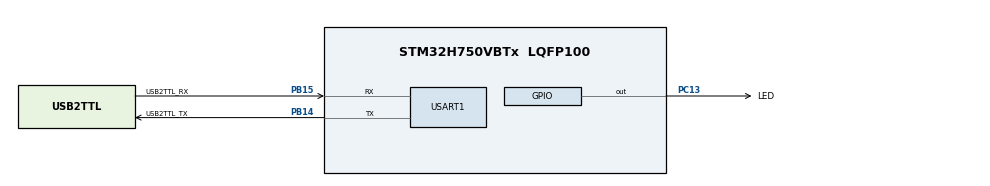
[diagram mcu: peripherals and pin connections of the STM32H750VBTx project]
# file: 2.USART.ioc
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Mcu.Family=STM32H7
Mcu.Name=STM32H750VBTx
Mcu.Package=LQFP100
NVIC.PriorityGroup=NVIC_PRIORITYGROUP_4
PA13\ (JTMS/SWDIO).Mode=Serial_Wire
PA13\ (JTMS/SWDIO).Signal=DEBUG_JTMS-SWDIO
PA14\ (JTCK/SWCLK).Mode=Serial_Wire
PA14\ (JTCK/SWCLK).Signal=DEBUG_JTCK-SWCLK
PB14.GPIO_Label=USB2TTL_TX
PB14.GPIO_PuPd=GPIO_PULLUP
PB14.GPIO_Speed=GPIO_SPEED_FREQ_LOW
PB14.Mode=Asynchronous
PB14.Signal=USART1_TX
PB15.GPIO_Label=USB2TTL_RX
PB15.GPIO_PuPd=GPIO_PULLUP
PB15.GPIO_Speed=GPIO_SPEED_FREQ_LOW
PB15.Mode=Asynchronous
PB15.Signal=USART1_RX
PC13.GPIO_Label=LED
PC13.Signal=GPIO_Output
ProjectManager.HeapSize=0x200
ProjectManager.StackSize=0x400
ProjectManager.TargetToolchain=MDK-ARM V5.32
RCC.ADCFreq_Value=129000000
RCC.APB1Freq_Value=64000000
RCC.APB2Freq_Value=32000000
RCC.APB3Freq_Value=64000000
RCC.APB4Freq_Value=64000000
RCC.CortexFreq_Value=64000000
RCC.D2PPRE2=RCC_APB2_DIV2
RCC.HCLKFreq_Value=64000000
RCC.SYSCLKFreq_VALUE=64000000
RCC.USBFreq_Value=129000000
USART1.VirtualMode-Asynchronous=VM_ASYNC
board=custom

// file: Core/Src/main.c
/* USER CODE BEGIN Header */
/**
  ******************************************************************************
  * @file           : main.c
  * @brief          : Main program body
  ******************************************************************************
  * @attention
  *
  * Copyright (c) 2023 STMicroelectronics.
  * All rights reserved.
  *
  * This software is licensed under terms that can be found in the LICENSE file
  * in the root directory of this software component.
  * If no LICENSE file comes with this software, it is provided AS-IS.
  *
  ******************************************************************************
  */
/* USER CODE END Header */
#include "main.h"
#include "usart.h"
#include "gpio.h"

/* USER CODE BEGIN Includes */
#include "stdio.h"											//添加头文件stdio.h，keil的Options设置中勾选Use Microlib

/* USER CODE END Includes */

void SystemClock_Config(void);

int main(void)
{

  /* MCU Configuration--------------------------------------------------------*/

  /* Reset of all peripherals, Initializes the Flash interface and the Systick. */
  HAL_Init();

  /* Configure the system clock */
  SystemClock_Config();

  /* Initialize all configured peripherals */
  MX_GPIO_Init();
  MX_USART1_UART_Init();
  /* USER CODE BEGIN 2 */
	printf("HELLO WORLD!\n");								//打印语句
	printf("THIS IS Azure A1!\n");
	printf("输入任意字符继续\n");

	char c1 = 0;
	scanf("%c", &c1);
	printf("输入的字符是： %c", c1);

  /* USER CODE END 2 */

  /* Infinite loop */
  /* USER CODE BEGIN WHILE */
  while (1)
  {
	  HAL_GPIO_TogglePin(LED_GPIO_Port,LED_Pin);			//程序开始
	  HAL_Delay(500);

    /* USER CODE END WHILE */

  }
}

void SystemClock_Config(void)
{
  RCC_OscInitTypeDef RCC_OscInitStruct = {0};
  RCC_ClkInitTypeDef RCC_ClkInitStruct = {0};

  /** Supply configuration update enable
  */
  HAL_PWREx_ConfigSupply(PWR_LDO_SUPPLY);

  /** Configure the main internal regulator output voltage
  */
  __HAL_PWR_VOLTAGESCALING_CONFIG(PWR_REGULATOR_VOLTAGE_SCALE3);

  while(!__HAL_PWR_GET_FLAG(PWR_FLAG_VOSRDY)) {}

  /** Initializes the RCC Oscillators according to the specified parameters
  * in the RCC_OscInitTypeDef structure.
  */
  RCC_OscInitStruct.OscillatorType = RCC_OSCILLATORTYPE_HSI;
  RCC_OscInitStruct.HSIState = RCC_HSI_DIV1;
  RCC_OscInitStruct.HSICalibrationValue = RCC_HSICALIBRATION_DEFAULT;
  RCC_OscInitStruct.PLL.PLLState = RCC_PLL_NONE;
  if (HAL_RCC_OscConfig(&RCC_OscInitStruct) != HAL_OK)
  {
    Error_Handler();
  }

  /** Initializes the CPU, AHB and APB buses clocks
  */
  RCC_ClkInitStruct.ClockType = RCC_CLOCKTYPE_HCLK|RCC_CLOCKTYPE_SYSCLK
                              |RCC_CLOCKTYPE_PCLK1|RCC_CLOCKTYPE_PCLK2
                              |RCC_CLOCKTYPE_D3PCLK1|RCC_CLOCKTYPE_D1PCLK1;
  RCC_ClkInitStruct.SYSCLKSource = RCC_SYSCLKSOURCE_HSI;
  RCC_ClkInitStruct.SYSCLKDivider = RCC_SYSCLK_DIV1;
  RCC_ClkInitStruct.AHBCLKDivider = RCC_HCLK_DIV1;
  RCC_ClkInitStruct.APB3CLKDivider = RCC_APB3_DIV1;
  RCC_ClkInitStruct.APB1CLKDivider = RCC_APB1_DIV1;
  RCC_ClkInitStruct.APB2CLKDivider = RCC_APB2_DIV2;
  RCC_ClkInitStruct.APB4CLKDivider = RCC_APB4_DIV1;

  if (HAL_RCC_ClockConfig(&RCC_ClkInitStruct, FLASH_LATENCY_1) != HAL_OK)
  {
    Error_Handler();
  }
}

/* USER CODE BEGIN 4 */

#ifdef __GNUC__												//printf重定向
int _write(int fd, char *ptr, int len)
{
  HAL_UART_Transmit(&huart1, (uint8_t*)ptr, len, 0xFFFF);
  return len;
}
#else
int fputc(int ch, FILE *f)									//重定向c库函数printf到串口USART1，重定向后可使用printf函数
{
    /* 发送一个字节数据到串口USARTx */
	HAL_UART_Transmit(&huart1, (uint8_t *)&ch, 1, 0xFFFF);
	return (ch);
}

int fgetc(FILE *f)											//重定向c库函数scanf到串口USART1，重写向后可使用scanf、getchar等函数
{
	int ch;
	/* 等待串口输入数据 */
	while(__HAL_UART_GET_FLAG(&huart1, UART_FLAG_RXNE) == RESET);
	__HAL_UART_CLEAR_OREFLAG(&huart1);
	HAL_UART_Receive(&huart1, (uint8_t *)&ch, 1, 0xFFFF);
	return (ch);
}

#endif

/* USER CODE END 4 */

void Error_Handler(void)
{
  __disable_irq();
  while (1)
  {
  }
}
